# CH32V203G6U6 register map
Vendor: WCH; File version: 0.1.0
CPU: QingKe V4B V4B, little endian, no MPU, no FPU, vendor SysTick, 4 interrupt priority bits
Registers are 16-bit, read-write, reset 0x0 unless marked. A register's access mark holds for its fields unless they carry their own. Offsets are from the block's base; [hi:lo] are bit positions; lines under a group give offsets from that group; {n}, {i} and the like mark numbered series.

## EXTI — External interrupt/event controller
Base 0x40010400
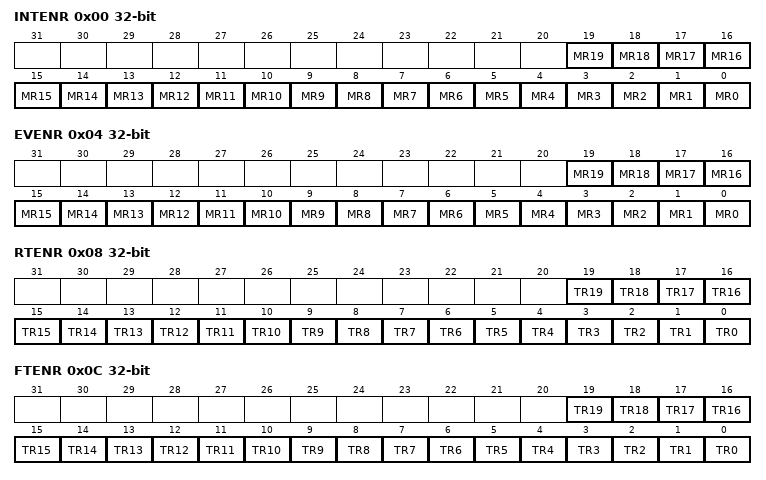
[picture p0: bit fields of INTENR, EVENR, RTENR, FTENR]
0x00 INTENR 32-bit — Interrupt mask register (EXTI_INTENR)
  [n] MR{n} (n=0..19) — Interrupt Mask on line {n}
0x04 EVENR 32-bit — Event mask register (EXTI_EVENR)
  [n] MR{n} (n=0..19) — Event Mask on line {n}
0x08 RTENR 32-bit — Rising Trigger selection register (EXTI_RTENR)
  [n] TR{n} (n=0..19) — Rising trigger event configuration of line {n}
0x0C FTENR 32-bit — Falling Trigger selection register (EXTI_FTENR)
  [n] TR{n} (n=0..19) — Falling trigger event configuration of line {n}
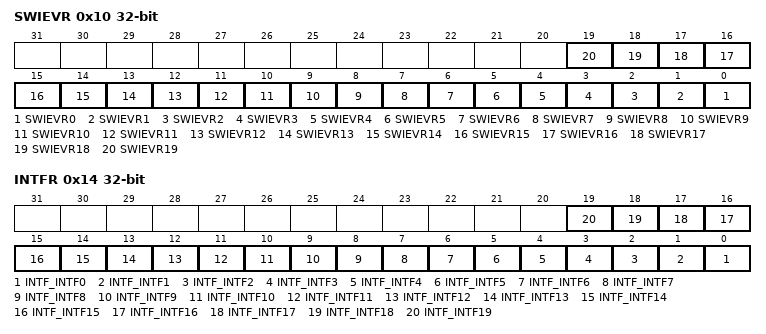
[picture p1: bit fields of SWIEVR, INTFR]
0x10 SWIEVR 32-bit — Software interrupt event register (EXTI_SWIEVR)
  [n] SWIEVR{n} (n=0..19)
0x14 INTFR 32-bit — Pending register (EXTI_INTFR)
  [n] INTF_INTF{n} (n=0..19)

## GPIOA — GPIO port A
Base 0x40010800
Same registers: GPIOB 0x40010C00, GPIOC 0x40011000, GPIOD 0x40011400
0x00 CFGLR 32-bit reset 0x44444444 — Port configuration register low (GPIOn_CFGLR)
0x04 CFGHR 32-bit reset 0x44444444 — Port configuration register high (GPIOn_CFGHR)
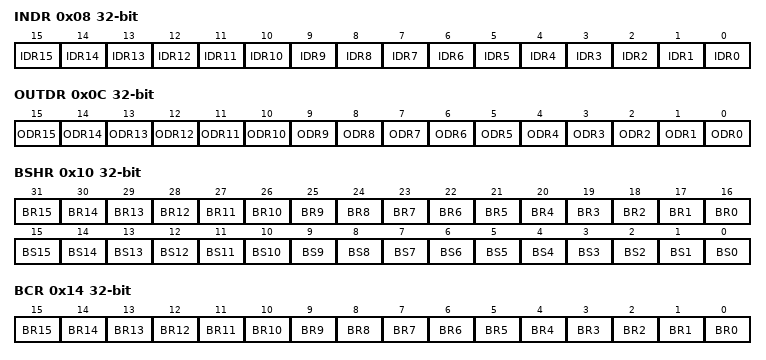
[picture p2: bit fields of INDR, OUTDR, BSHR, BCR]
0x08 INDR 32-bit — Port input data register (GPIOn_INDR)
  [n] IDR{n} (n=0..15) — Port input data
0x0C OUTDR 32-bit — Port output data register (GPIOn_OUTDR)
  [n] ODR{n} (n=0..15) — Port output data
0x10 BSHR 32-bit — Port bit set/reset register (GPIOn_BSHR)
  [n+16] BR{n} (n=0..15) — Reset bit {n}
  [n] BS{n} (n=3..15) — Set bit {n}
  [2] BS2 — Set bit 1
  [1] BS1 — Set bit 1
  [0] BS0 — Set bit 0
0x14 BCR 32-bit — Port bit reset register (GPIOn_BCR)
  [n] BR{n} (n=3..15) — Reset bit {n}
  [2] BR2 — Reset bit 1
  [1] BR1 — Reset bit 1
  [0] BR0 — Reset bit 0
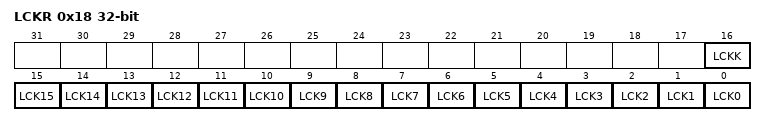
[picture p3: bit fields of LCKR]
0x18 LCKR 32-bit — Port configuration lock register
  [16] LCKK — Lock key
  [n] LCK{n} (n=0..15) — Port A Lock bit {n}

## SPI1 — SPI controller 1
Base 0x40013000
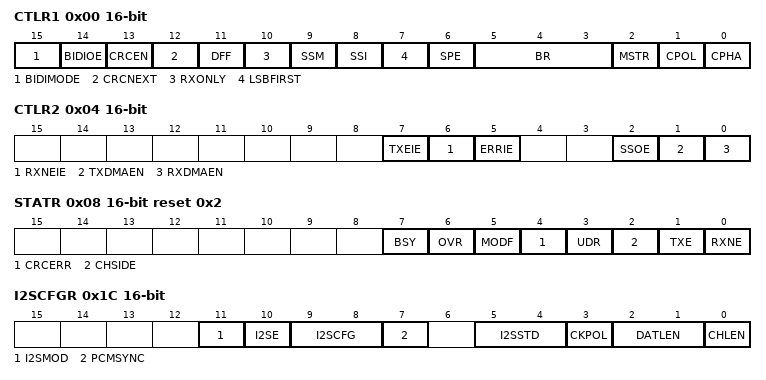
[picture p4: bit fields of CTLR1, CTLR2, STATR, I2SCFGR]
0x00 CTLR1 — control register 1
  [15] BIDIMODE — Bidirectional data mode enable
  [14] BIDIOE — Output enable in bidirectional mode
  [13] CRCEN — Hardware CRC calculation enable
  [12] CRCNEXT — CRC transfer next
  [11] DFF — Data frame format
  [10] RXONLY — Receive only
  [9] SSM — Software slave management
  [8] SSI — Internal slave select
  [7] LSBFIRST — Frame format
  [6] SPE — SPI enable
  [5:3] BR — Baud rate control
  [2] MSTR — Master selection
  [1] CPOL — Clock polarity
  [0] CPHA — Clock phase
0x04 CTLR2 — control register 2
  [7] TXEIE — Tx buffer empty interrupt enable
  [6] RXNEIE — RX buffer not empty interrupt enable
  [5] ERRIE — Error interrupt enable
  [2] SSOE — SS output enable
  [1] TXDMAEN — Tx buffer DMA enable
  [0] RXDMAEN — Rx buffer DMA enable
0x08 STATR reset 0x2 — status register
  [7] BSY ro — Busy flag
  [6] OVR — Overrun flag
  [5] MODF ro — Mode fault
  [4] CRCERR — CRC error flag
  [3] UDR ro — Underrun flag
  [2] CHSIDE
  [1] TXE ro — Transmit buffer empty
  [0] RXNE ro — Receive buffer not empty
0x0C DATAR — data register
  [15:0] DR
0x10 CRCR reset 0x7 — CRCR polynomial register
  [15:0] CRCPOLY — CRC polynomial register
0x14 RCRCR — RX CRC register
  [15:0] RXCRC
0x18 TCRCR — send CRC register
  [15:0] TXCRC
0x1C I2SCFGR reset not defined — SPI_I2S configure register
  [11] I2SMOD, [10] I2SE, [9:8] I2SCFG, [7] PCMSYNC, [5:4] I2SSTD, [3] CKPOL, [2:1] DATLEN, [0] CHLEN
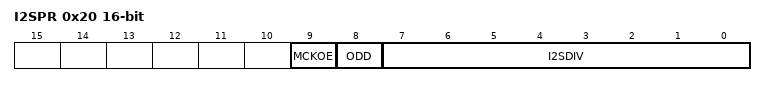
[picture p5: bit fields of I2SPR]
0x20 I2SPR reset not defined
  [9] MCKOE, [8] ODD, [7:0] I2SDIV
0x24 HSCR — high speed control register

## DMA1 — General-purpose DMA controller
Base 0x40020000
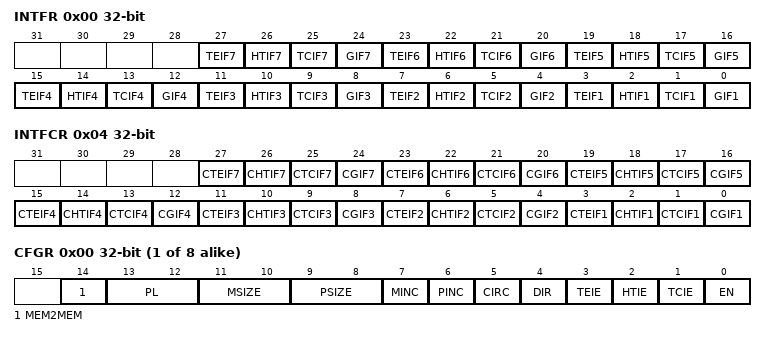
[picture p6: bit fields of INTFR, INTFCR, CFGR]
0x00 INTFR 32-bit — DMA interrupt status register (DMA_INTFR)
  [4n-1] TEIF{n} (n=1..7) — Channel {n} Transfer Error flag
  [4n-2] HTIF{n} (n=1..7) — Channel {n} Half Transfer Complete flag
  [4n-3] TCIF{n} (n=1..7) — Channel {n} Transfer Complete flag
  [4n-4] GIF{n} (n=1..7) — Channel {n} Global interrupt flag
0x04 INTFCR 32-bit — DMA interrupt flag clear register (DMA_INTFCR)
  [4n-1] CTEIF{n} (n=1..7) — Channel {n} Transfer Error clear
  [4n-2] CHTIF{n} (n=1..7) — Channel {n} Half Transfer clear
  [4n-3] CTCIF{n} (n=1..7) — Channel {n} Transfer Complete clear
  [4n-4] CGIF{n} (n=1..7) — Channel {n} Global interrupt clear
{0x8+0x14*i} Channel{i} (i=0..7) group
  0x00 CFGR 32-bit reset not defined — DMA channel configuration register (DMA_CFGR)
    [14] MEM2MEM — Memory to memory mode
    [13:12] PL — Channel Priority level
    [11:10] MSIZE — Memory size
    [9:8] PSIZE — Peripheral size
    [7] MINC — Memory increment mode
    [6] PINC — Peripheral increment mode
    [5] CIRC — Circular mode
    [4] DIR — Data transfer direction
    [3] TEIE — Transfer error interrupt enable
    [2] HTIE — Half Transfer interrupt enable
    [1] TCIE — Transfer complete interrupt enable
    [0] EN — Channel enable
  0x04 CNTR 32-bit reset not defined — DMA channel 1 number of data register
    [15:0] NDT — Number of data to transfer
  0x08 PADDR 32-bit reset not defined — DMA channel 1 peripheral address register
    [31:0] PA — Peripheral address
  0x0C MADDR 32-bit reset not defined — DMA channel 1 memory address register
    [31:0] MA — Memory address

## PFIC — Program Fast Interrupt Controller
Base 0xE000E000
0xD10 SCTLR 32-bit reset not defined — PFIC system control register.
  [31] SYSRESET — Request an MCU-wide software reset.

## FLASH — Flash interface controller
Base 0x40022000
0x00 ACTLR 32-bit reset not defined
0x04 KEYR 32-bit — Flash key register
  [31:0] FKEYR
0x08 OBKEYR 32-bit — Flash option key register
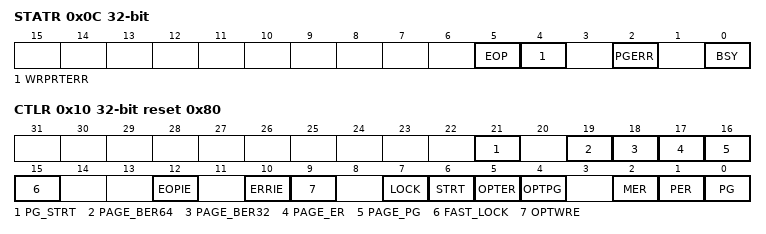
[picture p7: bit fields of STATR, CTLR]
0x0C STATR 32-bit — Status register
  [5] EOP — End of operation
  [4] WRPRTERR — Write protection error
  [2] PGERR
  [0] BSY ro — Busy
0x10 CTLR 32-bit reset 0x80 — Control register
  [21] PG_STRT
  [19] PAGE_BER64
  [18] PAGE_BER32
  [17] PAGE_ER — Fast erase
  [16] PAGE_PG — Fast programming
  [15] FAST_LOCK
  [12] EOPIE — End of operation interrupt enable
  [10] ERRIE — Error interrupt enable
  [9] OPTWRE
  [7] LOCK
  [6] STRT — Start
  [5] OPTER
  [4] OPTPG
  [2] MER — Mass Erase
  [1] PER — Page Erase
  [0] PG — Programming
0x14 ADDR 32-bit — Flash address register
  [31:0] FAR — Flash Address
0x1C OBR 32-bit reset 0x3FFFFFC — Option byte register
  [5] BFB2
  [9:2] USER
  [2] WDG_SW
  [1] RDPRT — Read protection
  [0] OPTERR
0x20 WPR 32-bit reset 0xFFFFFFFF — Write protection register
  [31:0] WRP — Write protect
0x24 MODEKEYR 32-bit — Mode select register

## CRC — CRC calculation unit
Base 0x40023000
0x00 DATAR 32-bit reset 0xFFFFFFFF — Data register
  [31:0] DR — Data Register
0x04 IDATAR 8-bit — Independent Data register
  [7:0] IDR_IDATAR
0x08 CTLR 32-bit — Control register
  [0] RESET — Reset bit

## OPA — Dual operational-amplifier / comparator block
Base 0x40023804
0x00 CR 32-bit — Control register
